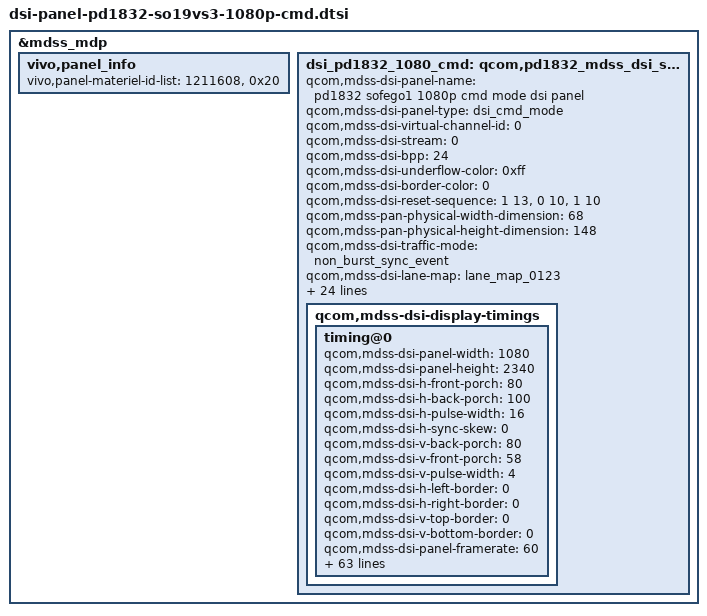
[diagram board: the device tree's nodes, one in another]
/* Copyright (c) 2018, The Linux Foundation. All rights reserved.
 *
 * This program is free software; you can redistribute it and/or modify
 * it under the terms of the GNU General Public License version 2 and
 * only version 2 as published by the Free Software Foundation.
 *
 * This program is distributed in the hope that it will be useful,
 * but WITHOUT ANY WARRANTY; without even the implied warranty of
 * MERCHANTABILITY or FITNESS FOR A PARTICULAR PURPOSE.  See the
 * GNU General Public License for more details.
 */

&mdss_mdp {
	/* vivo panel materiel info start */
		/* No add new id until you have import driver for new panel ok!!!!!! */
		vivo,panel_info {
			/* vivo,panel-materiel-id-list = "materiel_id1", "lcm1_sf_id1 lcm1_sf_id2 lcm1_sf_id3...",
						"materiel_id2", "lcm2_sf_id1 lcm2_sf_id2 lcm2_sf_id3...",
						...
						"materiel_idX, "lcmX_sf_id1, lcmX_sf_id2, lcmX_sf_id3...";
			*/
			vivo,panel-materiel-id-list = "1211608", "0x20";	/*S6E3FC2*/
		};
		/* vivo panel materiel info end */

	dsi_pd1832_1080_cmd: qcom,pd1832_mdss_dsi_sofego1_1080p_cmd {
		qcom,mdss-dsi-panel-name = "pd1832 sofego1 1080p cmd mode dsi panel";
		qcom,mdss-dsi-panel-type = "dsi_cmd_mode";
		//qcom,mdss-dsi-panel-clockrate = <1140000000>;
		qcom,mdss-dsi-virtual-channel-id = <0>;
		qcom,mdss-dsi-stream = <0>;
		qcom,mdss-dsi-bpp = <24>;
		qcom,mdss-dsi-underflow-color = <0xff>;
		qcom,mdss-dsi-border-color = <0>;
		qcom,mdss-dsi-reset-sequence = <1 13>, <0 10>, <1 10>;
		qcom,mdss-pan-physical-width-dimension = <68>;
		qcom,mdss-pan-physical-height-dimension = <148>;
		qcom,mdss-dsi-traffic-mode = "non_burst_sync_event";
		qcom,mdss-dsi-lane-map = "lane_map_0123";
		qcom,mdss-dsi-bllp-eof-power-mode;
		qcom,mdss-dsi-bllp-power-mode;
		qcom,mdss-dsi-lane-0-state;
		qcom,mdss-dsi-lane-1-state;
		qcom,mdss-dsi-lane-2-state;
		qcom,mdss-dsi-lane-3-state;
		qcom,mdss-dsi-dma-trigger = "trigger_sw";
		qcom,mdss-dsi-mdp-trigger = "none";
		qcom,mdss-dsi-te-pin-select = <1>;
		qcom,mdss-dsi-wr-mem-start = <0x2c>;
		qcom,mdss-dsi-wr-mem-continue = <0x3c>;
		qcom,mdss-dsi-te-dcs-command = <1>;
		qcom,mdss-dsi-te-check-enable;
		qcom,mdss-dsi-te-using-te-pin;
		qcom,mdss-dsi-panel-id = <0x20>;
		qcom,mdss-dsi-project-name = "pd1832";
		qcom,mdss-panel-sre;
		qcom,dynamic-dsi-timing-enable;
		qcom,mdss-dsi-panel-clockrate = <1140000000>;
		qcom,mdss-dsi-panel-intent-clockrate = <1130000000>;
		qcom,vivo-dsi-panel-type = "oled";
		qcom,mdss-dsi-panel-physical-type = "oled";
		qcom,ud-fingerprint-support;

		qcom,mdss-dsi-display-timings {
			timing@0{
				qcom,mdss-dsi-panel-width = <1080>;
				qcom,mdss-dsi-panel-height = <2340>;
				qcom,mdss-dsi-h-front-porch = <80>;
				qcom,mdss-dsi-h-back-porch = <100>;
				qcom,mdss-dsi-h-pulse-width = <16>;
				qcom,mdss-dsi-h-sync-skew = <0>;
				qcom,mdss-dsi-v-back-porch = <80>;
				qcom,mdss-dsi-v-front-porch = <58>;
				qcom,mdss-dsi-v-pulse-width = <4>;
				qcom,mdss-dsi-h-left-border = <0>;
				qcom,mdss-dsi-h-right-border = <0>;
				qcom,mdss-dsi-v-top-border = <0>;
				qcom,mdss-dsi-v-bottom-border = <0>;
				qcom,mdss-dsi-panel-framerate = <60>;
				qcom,mdss-dsi-panel-clockrate = <1140000000>;
				qcom,mdss-dsi-on-command = [
					/* Sleep Out */
					39 01 00 00 00 00 03 9F A5 A5
					39 01 00 00 15 00 02 11 00
					39 01 00 00 00 00 03 9F 5A 5A
					/* Common Setting */
					39 01 00 00 00 00 03 9F A5 A5
					39 01 00 00 00 00 02 35 00
					39 01 00 00 00 00 03 9F 5A 5A
					/* ESD S/W work around*/
					39 01 00 00 00 00 03 FC 5A 5A
					39 01 00 00 00 00 02 B0 01
					39 01 00 00 00 00 02 E3 88
					39 01 00 00 00 00 02 B0 07
					39 01 00 00 00 00 02 ED 67
					39 01 00 00 00 00 03 FC A5 A5
					/* Brightness Setting */
					39 01 00 00 00 00 03 F0 5A 5A
					39 01 00 00 00 00 02 B0 07
					39 01 00 00 00 00 02 B7 01
					39 01 00 00 00 00 03 F0 A5 A5
					39 01 00 00 65 00 02 53 20
					39 01 00 00 00 00 02 55 00
					/* Display On */
					39 01 00 00 00 00 03 9F A5 A5
					39 01 00 00 00 00 02 29 00
					39 01 00 00 00 00 03 9F 5A 5A
					39 01 00 00 00 00 03 F0 5A 5A
					/* ACL dimming setting */
					39 01 00 00 00 00 02 B0 DE
					39 01 00 00 00 00 02 B9 48

					/* seed setting*/
					39 01 00 00 00 00 02 81 90
					39 01 00 00 00 00 18 B1 00 00 FF 02 00 18 FF 01 03 0D FF 1D FF E4 FF 0F F1 FF F8 01 FF FF FF
					/* up/down area Magenta/Greenish */
					39 01 00 00 00 00 03 B6 00 02

					/* TCS Target Color Skin setting */
					39 01 00 00 00 00 02 B0 1C
					39 01 00 00 00 00 02 B3 00
					39 01 00 00 00 00 02 B0 23
					39 01 00 00 00 00 02 B3 91
					39 01 00 00 00 00 02 B0 21
					39 01 00 00 00 00 02 B3 F8
					39 01 00 00 00 00 02 83 80
					39 01 00 00 00 00 03 B3 00 C0

					39 01 00 00 00 00 03 F0 A5 A5
				];

				/* samsung OLED ORE mode */
				qcom,mdss-oled-seed-ore-on-command =
				[
					39 00 00 00 00 00 03 F0 5A 5A
					39 00 00 00 00 00 03 87 80 00
					39 00 00 00 00 00 02 B0 52
					39 00 00 00 00 00 02 B3 00
					39 01 00 00 00 00 03 F0 A5 A5
				];

				qcom,mdss-oled-seed-ore-off-command =
				[
					39 00 00 00 00 00 03 F0 5A 5A
					39 00 00 00 00 00 02 B0 52
					39 00 00 00 00 00 02 B3 01
					39 01 00 00 00 00 03 F0 A5 A5
				];

				/* samsung OLED CRC mode */
				qcom,mdss-oled-seed-crc-on-command-p3 =
				[
					39 01 00 00 00 00 03 F0 5A 5A
					39 01 00 00 00 00 02 81 90
					39 01 00 00 00 00 18 B1 00 00 FF 03 00 18 FF 01 03 0D FF 1D FF E4 FF 0F F1 FF F8 01 FF FF FF
					39 01 00 00 00 00 03 F0 A5 A5
				];

				/* samsung OLED HBM mode */
				qcom,mdss-oled-seed-crc-on-command-srgb =
				[
					39 01 00 00 00 00 03 F0 5A 5A
					39 01 00 00 00 00 02 81 90
					39 01 00 00 00 00 18 B1 00 00 B7 0D 05 3F CE 14 04 07 A9 50 E8 D1 C7 14 C8 E6 E2 1F FF FD DE
					39 01 00 00 00 00 03 F0 A5 A5
				];

				qcom,mdss-oled-seed-crc-off-command =
				[
					39 01 00 00 00 00 03 F0 5A 5A
					39 01 00 00 00 00 02 81 00
					39 01 00 00 00 00 03 B1 00 01
					39 01 00 00 00 00 03 F0 A5 A5
				];

				/* samsung OLED HBM mode */
				qcom,mdss-oled-hbm-on-command-level1 =
				[
					39 01 00 00 00 00 03 F0 5A 5A
					39 01 00 00 00 00 02 B0 07
					39 01 00 00 00 00 02 B7 28
					39 01 00 00 00 00 03 F0 A5 A5
					39 01 00 00 11 00 02 53 28
					39 01 00 00 00 00 02 53 E8
					39 01 00 00 00 00 03 51 00 D8
				];

				qcom,mdss-oled-hbm-on-command-level2 =
				[
					39 01 00 00 00 00 03 F0 5A 5A
					39 01 00 00 00 00 02 B0 07
					39 01 00 00 00 00 02 B7 28
					39 01 00 00 00 00 03 F0 A5 A5
					39 01 00 00 11 00 02 53 28
					39 01 00 00 00 00 02 53 E8
					39 01 00 00 00 00 03 51 03 FF
				];

				qcom,mdss-oled-hbm-on-command-ud-fingerprint =
				[
					39 00 00 00 00 00 03 F0 5A 5A
					39 00 00 00 00 00 04 B7 00 01 5B
					39 00 00 00 00 00 03 F0 A5 A5
					39 00 00 00 00 00 02 53 E0
					39 01 00 00 00 00 03 51 03 FF
				];

				qcom,mdss-oled-ps-off-command =
				[
					39 00 00 00 00 00 03 F0 5A 5A
					39 00 00 00 00 00 03 BD 00 00
					39 00 00 00 00 00 04 B7 00 01 53
					39 01 00 00 00 00 03 F0 A5 A5
				];

				qcom,mdss-oled-ps-on-command =
				[
					39 00 00 00 00 00 03 F0 5A 5A
					39 00 00 00 00 00 03 BD 00 02
					39 00 00 00 00 00 03 F0 A5 A5
				];

				qcom,mdss-oled-hbm-off-command =
				[
					39 01 00 00 00 00 02 53 28
				];

				qcom,mdss-oled-hbm-off-command-ud-fingerprint =
				[
					39 00 00 00 00 00 03 F0 5A 5A
					39 00 00 00 00 00 03 BD 00 02
					39 00 00 00 00 00 03 F0 A5 A5
					39 01 00 00 00 00 02 53 20
				];

				qcom,mdss-oled-acl-on-command-level1 =
				[
					39 01 00 00 00 00 02 55 01
				];

				qcom,mdss-oled-acl-on-command-level2 =
				[
					39 01 00 00 00 00 02 55 02
				];

				qcom,mdss-oled-acl-on-command-level3 =
				[
					39 01 00 00 00 00 02 55 03
				];

				qcom,mdss-oled-acl-off-command =
				[
					39 01 00 00 00 00 02 55 00
				];

				qcom,mdss-oled-dimming-speed =
				[
					39 01 00 00 00 00 03 F0 5A 5A
					39 01 00 00 00 00 02 B0 07
					39 01 00 00 00 00 02 B7 28
					39 01 00 00 00 00 03 F0 A5 A5
					39 01 00 00 00 00 02 53 28
				];

				qcom,mdss-oled-dimming-speed-off =
				[
					39 01 00 00 00 00 02 53 20
				];

				/* samsung OLED AOD mode, defaut mode  HLPM high brightness */
				qcom,mdss-oled-aod-on-command =
				[
					39 01 00 00 00 00 03 9F A5 A5
					39 01 00 00 11 00 02 28 00
					39 01 00 00 00 00 03 9F 5A 5A

					39 01 00 00 00 00 03 F0 5A 5A
					39 01 00 00 00 00 02 B0 DF
					39 01 00 00 00 00 05 B8 04 01 84 92
					39 01 00 00 00 00 03 F0 A5 A5

					39 01 00 00 00 00 03 9F A5 A5
					39 01 00 00 00 00 02 13 00
					39 01 00 00 00 00 03 9F 5A 5A
				
					39 01 00 00 00 00 03 F0 5A 5A
					39 01 00 00 00 00 02 B0 DF
					39 01 00 00 00 00 05 B8 02 C1 00 5D
					39 01 00 00 00 00 02 B0 69
					/* 50nit 4CYC/4CYC */
					39 01 00 00 00 00 06 B9 05 09 1A 05 0A
					39 01 00 00 00 00 02 B0 0B
					39 01 00 00 00 00 02 F4 6C
					39 01 00 00 00 00 02 53 22
					39 01 00 00 00 00 02 B0 A5
					39 01 00 00 00 00 02 C7 00
					39 01 00 00 00 00 03 F0 A5 A5
				];

				qcom,mdss-oled-alpm-hbirghtness-on-command =
				[
					39 01 00 00 00 00 03 F0 5A 5A
					39 01 00 00 00 00 02 B0 DF
					39 01 00 00 00 00 05 B8 04 01 84 92
					39 01 00 00 00 00 02 B0 69
					39 01 00 00 00 00 06 B9 08 08 D0 08 0E
					39 01 00 00 00 00 02 B0 0B
					39 01 00 00 00 00 02 F4 6C
					39 01 00 00 00 00 02 53 22
					39 01 00 00 00 00 02 B0 A5
					39 01 00 00 00 00 02 C7 01
					39 01 00 00 00 00 03 F0 A5 A5

					39 01 00 00 00 00 03 9F A5 A5
					39 01 00 00 00 00 02 29 00
					39 01 00 00 00 00 03 9F 5A 5A
				];

				qcom,mdss-oled-alpm-lbirghtness-on-command =
				[
					39 01 00 00 00 00 03 F0 5A 5A
					39 01 00 00 00 00 02 B0 DF
					39 01 00 00 00 00 05 B8 04 01 84 92
					39 01 00 00 00 00 02 B0 69
					39 01 00 00 00 00 06 B9 08 08 D0 08 0E
					39 01 00 00 00 00 02 B0 0B
					39 01 00 00 00 00 02 F4 6C
					39 01 00 00 00 00 02 53 23
					39 01 00 00 00 00 02 B0 A5
					39 01 00 00 00 00 02 C7 01
					39 01 00 00 00 00 03 F0 A5 A5

					39 01 00 00 00 00 03 9F A5 A5
					39 01 00 00 00 00 02 29 00
					39 01 00 00 00 00 03 9F 5A 5A
				];

				qcom,mdss-oled-hlpm-hbirghtness-on-command =
				[
					39 01 00 00 00 00 03 F0 5A 5A
					39 01 00 00 00 00 02 B0 DF
					39 01 00 00 00 00 05 B8 04 01 84 92
					39 01 00 00 00 00 02 B0 69
					39 01 00 00 00 00 06 B9 08 08 D0 08 0E
					39 01 00 00 00 00 02 B0 0B
					39 01 00 00 00 00 02 F4 6C
					39 01 00 00 00 00 02 53 22
					39 01 00 00 00 00 02 B0 A5
					39 01 00 00 00 00 02 C7 00
					39 01 00 00 00 00 03 F0 A5 A5

					39 01 00 00 00 00 03 9F A5 A5
					39 01 00 00 00 00 02 29 00
					39 01 00 00 00 00 03 9F 5A 5A
				];

				qcom,mdss-oled-hlpm-lbirghtness-on-command =
				[
					39 01 00 00 00 00 03 F0 5A 5A
					39 01 00 00 00 00 02 B0 DF
					39 01 00 00 00 00 05 B8 04 01 84 92
					39 01 00 00 00 00 02 B0 69
					39 01 00 00 00 00 06 B9 08 08 D0 08 0E
					39 01 00 00 00 00 02 B0 0B
					39 01 00 00 00 00 02 F4 6C
					39 01 00 00 00 00 02 53 23
					39 01 00 00 00 00 02 B0 A5
					39 01 00 00 00 00 02 C7 00
					39 01 00 00 00 00 03 F0 A5 A5

					39 01 00 00 00 00 03 9F A5 A5
					39 01 00 00 00 00 02 29 00
					39 01 00 00 00 00 03 9F 5A 5A
				];

				qcom,mdss-oled-aod-off-command =
				[
					39 01 00 00 00 00 02 53 28
				];

				qcom,mdss-oled-aod-off-command-bsp-test =
				[
					39 01 00 00 00 00 03 9F A5 A5
					39 01 00 00 11 00 02 22 00
					39 01 00 00 11 00 02 28 00
					39 01 00 00 00 00 03 9F 5A 5A
					39 01 00 00 00 00 02 53 28
					39 01 00 00 00 00 03 9F A5 A5
					39 01 00 00 00 00 02 13 00
					39 01 00 00 00 00 02 29 00
					39 01 00 00 00 00 03 9F 5A 5A
				];

				qcom,mdss-oled-display-on-command =
				[
					39 01 00 00 00 00 02 53 20
					39 01 00 00 00 00 03 9F A5 A5
					39 01 00 00 00 00 02 13 00
					39 01 00 00 00 00 02 29 00
					39 01 00 00 00 00 03 9F 5A 5A
				];

				/*set aod mode display on*/
				qcom,mdss-oled-aod-on-display-on-command =
				[
					39 01 00 00 00 00 03 9F A5 A5
					39 01 00 00 00 00 02 29 00
					39 01 00 00 00 00 03 9F 5A 5A
				];

				qcom,mdss-alpm-command-state = "dsi_lp_mode";
				qcom,mdss-dsi-off-command = [
					39 01 00 00 00 00 03 9F A5 A5
					39 01 00 00 0B 00 02 28 00
					39 01 00 00 00 00 02 10 00
					39 01 00 00 00 00 03 9F 5A 5A
					39 01 00 00 00 00 03 F0 5A 5A
					39 01 00 00 00 00 02 B0 05
					39 01 00 00 00 00 02 F4 01
					39 01 00 00 97 00 03 F0 A5 A5
					];
		qcom,mdss-dsi-on-command-state = "dsi_lp_mode";
		qcom,mdss-dsi-off-command-state = "dsi_lp_mode";
		qcom,mdss-dsi-h-sync-pulse = <0>;
		};
		};
	};
};
